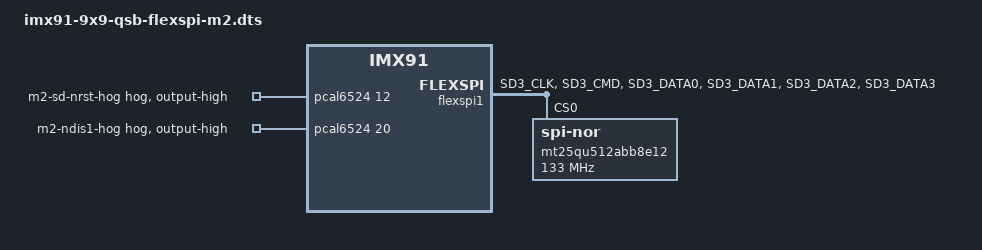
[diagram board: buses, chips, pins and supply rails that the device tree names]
// SPDX-License-Identifier: (GPL-2.0+ OR MIT)
/*
 * Copyright 2024 NXP
 *
 */

#include "imx91-9x9-qsb.dts"

&reg_usdhc3_vmmc {
	status = "disabled";
};

&usdhc3_pwrseq {
	status = "disabled";
};

&usdhc3 {
	status = "disabled";
};

&pcal6524 {
	/*
	 * need the SD3_QSPI_SEL to 0, to select the M.2 pad.
	 * default dts already set the sd3-qspi-sel-hog to low.
	 * so no need to seting here.
	 */

	/* Put the nor reset pin(M2_SD_nRST) to High */
	m2-sd-nrst-hog {
		gpio-hog;
		gpios = <12 GPIO_ACTIVE_HIGH>;
		output-high;
	};

	/* Give M.2 nor chip 1.8v(M2_nDIS1 to High) */
	m2-ndis1-hog {
		gpio-hog;
		gpios = <20 GPIO_ACTIVE_HIGH>;
		output-high;
	};

};

&flexspi1 {
	pinctrl-names = "default";
	pinctrl-0 = <&pinctrl_flexspi1>;
	status = "okay";

	mt25qu512abb8e12: flash@0 {
		reg = <0>;
		#address-cells = <1>;
		#size-cells = <1>;
		compatible = "jedec,spi-nor";
		spi-max-frequency = <133000000>;
		spi-tx-bus-width = <4>;
		spi-rx-bus-width = <4>;
	};
};

&iomuxc {
	pinctrl_flexspi1: flexspi1grp {
		fsl,pins = <
			MX91_PAD_SD3_CLK__FLEXSPI1_A_SCLK	0x3fe
			MX91_PAD_SD3_CMD__FLEXSPI1_A_SS0_B	0x3fe
			MX91_PAD_SD3_DATA0__FLEXSPI1_A_DATA0	0x3fe
			MX91_PAD_SD3_DATA1__FLEXSPI1_A_DATA1	0x3fe
			MX91_PAD_SD3_DATA2__FLEXSPI1_A_DATA2	0x3fe
			MX91_PAD_SD3_DATA3__FLEXSPI1_A_DATA3	0x3fe
		>;
	};
};
